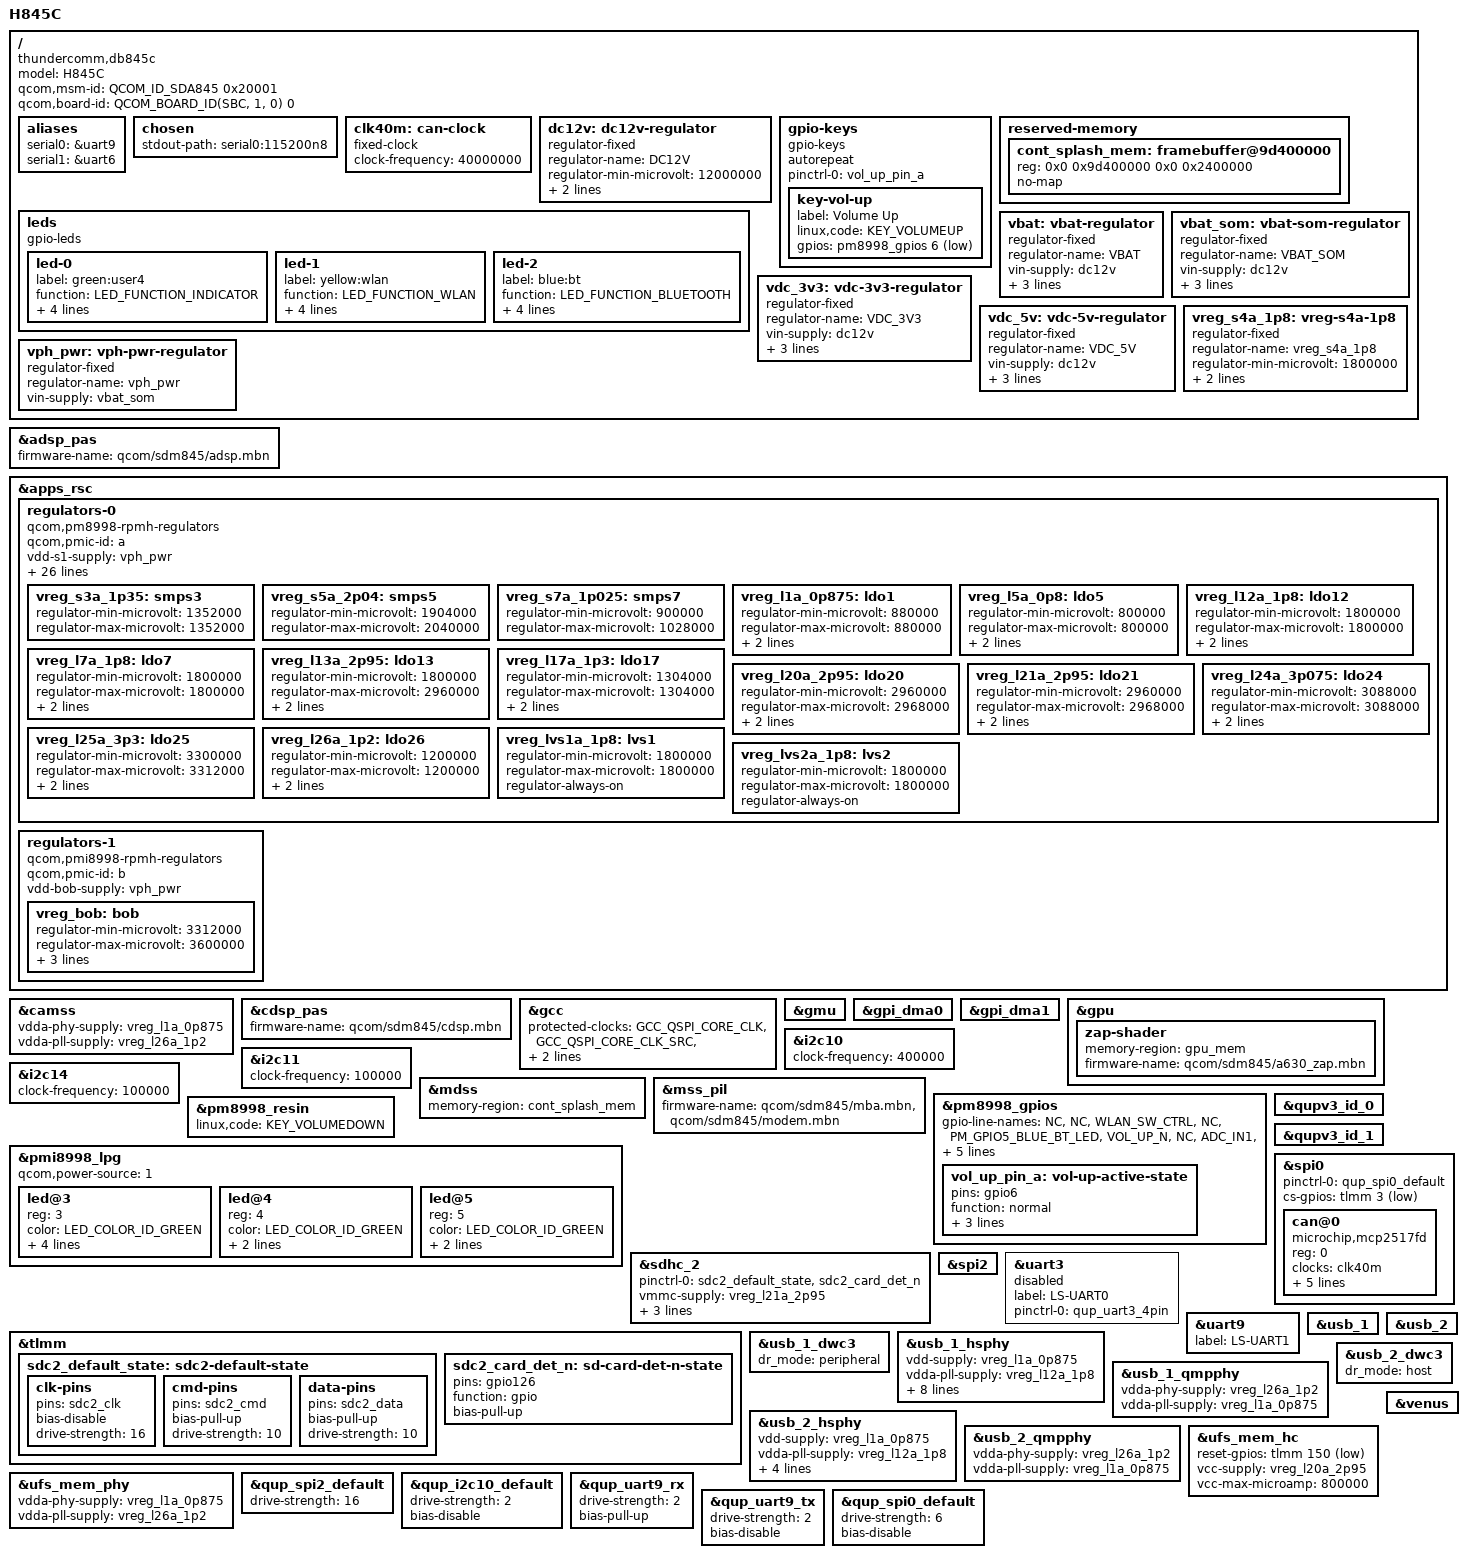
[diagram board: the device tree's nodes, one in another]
// SPDX-License-Identifier: GPL-2.0
/*
 * Copyright (c) 2019, Linaro Ltd.
 */

/dts-v1/;

#include <dt-bindings/arm/qcom,ids.h>
#include <dt-bindings/leds/common.h>
#include <dt-bindings/pinctrl/qcom,pmic-gpio.h>
#include <dt-bindings/regulator/qcom,rpmh-regulator.h>
#include <dt-bindings/sound/qcom,q6afe.h>
#include <dt-bindings/sound/qcom,q6asm.h>
#include "sdm845.dtsi"
#include "pm8998.dtsi"
#include "pmi8998.dtsi"

/ {
	model = "H845C";
	compatible = "thundercomm,db845c", "qcom,sdm845";
	qcom,msm-id = <QCOM_ID_SDA845 0x20001>;
	qcom,board-id = <QCOM_BOARD_ID(SBC, 1, 0) 0>;

	aliases {
		serial0 = &uart9;
		serial1 = &uart6;
	};

	chosen {
		stdout-path = "serial0:115200n8";
	};

	/* Fixed crystal oscillator dedicated to MCP2517FD */
	clk40m: can-clock {
		compatible = "fixed-clock";
		#clock-cells = <0>;
		clock-frequency = <40000000>;
	};

	dc12v: dc12v-regulator {
		compatible = "regulator-fixed";
		regulator-name = "DC12V";
		regulator-min-microvolt = <12000000>;
		regulator-max-microvolt = <12000000>;
		regulator-always-on;
	};

	gpio-keys {
		compatible = "gpio-keys";
		autorepeat;

		pinctrl-names = "default";
		pinctrl-0 = <&vol_up_pin_a>;

		key-vol-up {
			label = "Volume Up";
			linux,code = <KEY_VOLUMEUP>;
			gpios = <&pm8998_gpios 6 GPIO_ACTIVE_LOW>;
		};
	};

	leds {
		compatible = "gpio-leds";

		led-0 {
			label = "green:user4";
			function = LED_FUNCTION_INDICATOR;
			color = <LED_COLOR_ID_GREEN>;
			gpios = <&pm8998_gpios 13 GPIO_ACTIVE_HIGH>;
			default-state = "off";
			panic-indicator;
		};

		led-1 {
			label = "yellow:wlan";
			function = LED_FUNCTION_WLAN;
			color = <LED_COLOR_ID_YELLOW>;
			gpios = <&pm8998_gpios 9 GPIO_ACTIVE_HIGH>;
			linux,default-trigger = "phy0tx";
			default-state = "off";
		};

		led-2 {
			label = "blue:bt";
			function = LED_FUNCTION_BLUETOOTH;
			color = <LED_COLOR_ID_BLUE>;
			gpios = <&pm8998_gpios 5 GPIO_ACTIVE_HIGH>;
			linux,default-trigger = "bluetooth-power";
			default-state = "off";
		};
	};

	reserved-memory {
		/* Cont splash region set up by the bootloader */
		cont_splash_mem: framebuffer@9d400000 {
			reg = <0x0 0x9d400000 0x0 0x2400000>;
			no-map;
		};
	};

	vbat: vbat-regulator {
		compatible = "regulator-fixed";
		regulator-name = "VBAT";

		vin-supply = <&dc12v>;
		regulator-min-microvolt = <4200000>;
		regulator-max-microvolt = <4200000>;
		regulator-always-on;
	};

	vbat_som: vbat-som-regulator {
		compatible = "regulator-fixed";
		regulator-name = "VBAT_SOM";

		vin-supply = <&dc12v>;
		regulator-min-microvolt = <4200000>;
		regulator-max-microvolt = <4200000>;
		regulator-always-on;
	};

	vdc_3v3: vdc-3v3-regulator {
		compatible = "regulator-fixed";
		regulator-name = "VDC_3V3";
		vin-supply = <&dc12v>;
		regulator-min-microvolt = <3300000>;
		regulator-max-microvolt = <3300000>;
		regulator-always-on;
	};

	vdc_5v: vdc-5v-regulator {
		compatible = "regulator-fixed";
		regulator-name = "VDC_5V";

		vin-supply = <&dc12v>;
		regulator-min-microvolt = <500000>;
		regulator-max-microvolt = <500000>;
		regulator-always-on;
	};

	vreg_s4a_1p8: vreg-s4a-1p8 {
		compatible = "regulator-fixed";
		regulator-name = "vreg_s4a_1p8";

		regulator-min-microvolt = <1800000>;
		regulator-max-microvolt = <1800000>;
		regulator-always-on;
	};

	vph_pwr: vph-pwr-regulator {
		compatible = "regulator-fixed";
		regulator-name = "vph_pwr";

		vin-supply = <&vbat_som>;
	};
};

&adsp_pas {
	status = "okay";

	firmware-name = "qcom/sdm845/adsp.mbn";
};

&apps_rsc {
	regulators-0 {
		compatible = "qcom,pm8998-rpmh-regulators";
		qcom,pmic-id = "a";
		vdd-s1-supply = <&vph_pwr>;
		vdd-s2-supply = <&vph_pwr>;
		vdd-s3-supply = <&vph_pwr>;
		vdd-s4-supply = <&vph_pwr>;
		vdd-s5-supply = <&vph_pwr>;
		vdd-s6-supply = <&vph_pwr>;
		vdd-s7-supply = <&vph_pwr>;
		vdd-s8-supply = <&vph_pwr>;
		vdd-s9-supply = <&vph_pwr>;
		vdd-s10-supply = <&vph_pwr>;
		vdd-s11-supply = <&vph_pwr>;
		vdd-s12-supply = <&vph_pwr>;
		vdd-s13-supply = <&vph_pwr>;
		vdd-l1-l27-supply = <&vreg_s7a_1p025>;
		vdd-l2-l8-l17-supply = <&vreg_s3a_1p35>;
		vdd-l3-l11-supply = <&vreg_s7a_1p025>;
		vdd-l4-l5-supply = <&vreg_s7a_1p025>;
		vdd-l6-supply = <&vph_pwr>;
		vdd-l7-l12-l14-l15-supply = <&vreg_s5a_2p04>;
		vdd-l9-supply = <&vreg_bob>;
		vdd-l10-l23-l25-supply = <&vreg_bob>;
		vdd-l13-l19-l21-supply = <&vreg_bob>;
		vdd-l16-l28-supply = <&vreg_bob>;
		vdd-l18-l22-supply = <&vreg_bob>;
		vdd-l20-l24-supply = <&vreg_bob>;
		vdd-l26-supply = <&vreg_s3a_1p35>;
		vin-lvs-1-2-supply = <&vreg_s4a_1p8>;

		vreg_s3a_1p35: smps3 {
			regulator-min-microvolt = <1352000>;
			regulator-max-microvolt = <1352000>;
		};

		vreg_s5a_2p04: smps5 {
			regulator-min-microvolt = <1904000>;
			regulator-max-microvolt = <2040000>;
		};

		vreg_s7a_1p025: smps7 {
			regulator-min-microvolt = <900000>;
			regulator-max-microvolt = <1028000>;
		};

		vreg_l1a_0p875: ldo1 {
			regulator-min-microvolt = <880000>;
			regulator-max-microvolt = <880000>;
			regulator-initial-mode = <RPMH_REGULATOR_MODE_HPM>;
		};

		vreg_l5a_0p8: ldo5 {
			regulator-min-microvolt = <800000>;
			regulator-max-microvolt = <800000>;
			regulator-initial-mode = <RPMH_REGULATOR_MODE_HPM>;
		};

		vreg_l12a_1p8: ldo12 {
			regulator-min-microvolt = <1800000>;
			regulator-max-microvolt = <1800000>;
			regulator-initial-mode = <RPMH_REGULATOR_MODE_HPM>;
		};

		vreg_l7a_1p8: ldo7 {
			regulator-min-microvolt = <1800000>;
			regulator-max-microvolt = <1800000>;
			regulator-initial-mode = <RPMH_REGULATOR_MODE_HPM>;
		};

		vreg_l13a_2p95: ldo13 {
			regulator-min-microvolt = <1800000>;
			regulator-max-microvolt = <2960000>;
			regulator-initial-mode = <RPMH_REGULATOR_MODE_HPM>;
		};

		vreg_l17a_1p3: ldo17 {
			regulator-min-microvolt = <1304000>;
			regulator-max-microvolt = <1304000>;
			regulator-initial-mode = <RPMH_REGULATOR_MODE_HPM>;
		};

		vreg_l20a_2p95: ldo20 {
			regulator-min-microvolt = <2960000>;
			regulator-max-microvolt = <2968000>;
			regulator-initial-mode = <RPMH_REGULATOR_MODE_HPM>;
		};

		vreg_l21a_2p95: ldo21 {
			regulator-min-microvolt = <2960000>;
			regulator-max-microvolt = <2968000>;
			regulator-initial-mode = <RPMH_REGULATOR_MODE_HPM>;
		};

		vreg_l24a_3p075: ldo24 {
			regulator-min-microvolt = <3088000>;
			regulator-max-microvolt = <3088000>;
			regulator-initial-mode = <RPMH_REGULATOR_MODE_HPM>;
		};

		vreg_l25a_3p3: ldo25 {
			regulator-min-microvolt = <3300000>;
			regulator-max-microvolt = <3312000>;
			regulator-initial-mode = <RPMH_REGULATOR_MODE_HPM>;
		};

		vreg_l26a_1p2: ldo26 {
			regulator-min-microvolt = <1200000>;
			regulator-max-microvolt = <1200000>;
			regulator-initial-mode = <RPMH_REGULATOR_MODE_HPM>;
		};

		vreg_lvs1a_1p8: lvs1 {
			regulator-min-microvolt = <1800000>;
			regulator-max-microvolt = <1800000>;
			regulator-always-on;
		};

		vreg_lvs2a_1p8: lvs2 {
			regulator-min-microvolt = <1800000>;
			regulator-max-microvolt = <1800000>;
			regulator-always-on;
		};
	};

	regulators-1 {
		compatible = "qcom,pmi8998-rpmh-regulators";
		qcom,pmic-id = "b";

		vdd-bob-supply = <&vph_pwr>;

		vreg_bob: bob {
			regulator-min-microvolt = <3312000>;
			regulator-max-microvolt = <3600000>;
			regulator-initial-mode = <RPMH_REGULATOR_MODE_AUTO>;
			regulator-allow-bypass;
		};
	};
};

&camss {
	status = "okay";

	vdda-phy-supply = <&vreg_l1a_0p875>;
	vdda-pll-supply = <&vreg_l26a_1p2>;
};

&cdsp_pas {
	status = "okay";
	firmware-name = "qcom/sdm845/cdsp.mbn";
};

&gcc {
	protected-clocks = <GCC_QSPI_CORE_CLK>,
			   <GCC_QSPI_CORE_CLK_SRC>,
			   <GCC_QSPI_CNOC_PERIPH_AHB_CLK>,
			   <GCC_LPASS_Q6_AXI_CLK>,
			   <GCC_LPASS_SWAY_CLK>;
};

&gmu {
	status = "okay";
};

&gpi_dma0 {
	status = "okay";
};

&gpi_dma1 {
	status = "okay";
};

&gpu {
	status = "okay";
	zap-shader {
		memory-region = <&gpu_mem>;
		firmware-name = "qcom/sdm845/a630_zap.mbn";
	};
};

&i2c10 {
	status = "okay";
	clock-frequency = <400000>;
};

&i2c11 {
	/* On Low speed expansion */
	clock-frequency = <100000>;
	status = "okay";
};

&i2c14 {
	/* On Low speed expansion */
	clock-frequency = <100000>;
	status = "okay";
};

&mdss {
	memory-region = <&cont_splash_mem>;
	status = "okay";
};

&mss_pil {
	status = "okay";
	firmware-name = "qcom/sdm845/mba.mbn", "qcom/sdm845/modem.mbn";
};

&pm8998_gpios {
	gpio-line-names =
		"NC",
		"NC",
		"WLAN_SW_CTRL",
		"NC",
		"PM_GPIO5_BLUE_BT_LED",
		"VOL_UP_N",
		"NC",
		"ADC_IN1",
		"PM_GPIO9_YEL_WIFI_LED",
		"NC",
		"NC",
		"NC",
		"PM_GPIO13_GREEN_U4_LED",
		"DIV_CLK2",
		"NC",
		"NC",
		"NC",
		"SMB_STAT",
		"NC",
		"NC",
		"ADC_IN2",
		"OPTION1",
		"WCSS_PWR_REQ",
		"PM845_GPIO24",
		"OPTION2",
		"PM845_SLB";

	vol_up_pin_a: vol-up-active-state {
		pins = "gpio6";
		function = "normal";
		input-enable;
		bias-pull-up;
		qcom,drive-strength = <PMIC_GPIO_STRENGTH_NO>;
	};
};

&pm8998_resin {
	linux,code = <KEY_VOLUMEDOWN>;
	status = "okay";
};

&pmi8998_lpg {
	status = "okay";

	qcom,power-source = <1>;

	led@3 {
		reg = <3>;
		color = <LED_COLOR_ID_GREEN>;
		function = LED_FUNCTION_HEARTBEAT;
		function-enumerator = <3>;

		linux,default-trigger = "heartbeat";
		default-state = "on";
	};

	led@4 {
		reg = <4>;
		color = <LED_COLOR_ID_GREEN>;
		function = LED_FUNCTION_INDICATOR;
		function-enumerator = <2>;
	};

	led@5 {
		reg = <5>;
		color = <LED_COLOR_ID_GREEN>;
		function = LED_FUNCTION_INDICATOR;
		function-enumerator = <1>;
	};
};

&qupv3_id_0 {
	status = "okay";
};

&qupv3_id_1 {
	status = "okay";
};

&sdhc_2 {
	status = "okay";

	pinctrl-names = "default";
	pinctrl-0 = <&sdc2_default_state &sdc2_card_det_n>;

	vmmc-supply = <&vreg_l21a_2p95>;
	vqmmc-supply = <&vreg_l13a_2p95>;

	bus-width = <4>;
	cd-gpios = <&tlmm 126 GPIO_ACTIVE_LOW>;
};

&spi0 {
	status = "okay";
	pinctrl-names = "default";
	pinctrl-0 = <&qup_spi0_default>;
	cs-gpios = <&tlmm 3 GPIO_ACTIVE_LOW>;

	can@0 {
		compatible = "microchip,mcp2517fd";
		reg = <0>;
		clocks = <&clk40m>;
		interrupts-extended = <&tlmm 104 IRQ_TYPE_LEVEL_LOW>;
		spi-max-frequency = <10000000>;
		vdd-supply = <&vdc_5v>;
		xceiver-supply = <&vdc_5v>;
	};
};

&spi2 {
	/* On Low speed expansion */
	status = "okay";
};

&tlmm {
	sdc2_default_state: sdc2-default-state {
		clk-pins {
			pins = "sdc2_clk";
			bias-disable;

			/*
			 * It seems that mmc_test reports errors if drive
			 * strength is not 16 on clk, cmd, and data pins.
			 */
			drive-strength = <16>;
		};

		cmd-pins {
			pins = "sdc2_cmd";
			bias-pull-up;
			drive-strength = <10>;
		};

		data-pins {
			pins = "sdc2_data";
			bias-pull-up;
			drive-strength = <10>;
		};
	};

	sdc2_card_det_n: sd-card-det-n-state {
		pins = "gpio126";
		function = "gpio";
		bias-pull-up;
	};
};

&uart3 {
	label = "LS-UART0";
	pinctrl-0 = <&qup_uart3_4pin>;

	status = "disabled";
};

&uart9 {
	label = "LS-UART1";
	status = "okay";
};

&usb_1 {
	status = "okay";
};

&usb_1_dwc3 {
	dr_mode = "peripheral";
};

&usb_1_hsphy {
	status = "okay";

	vdd-supply = <&vreg_l1a_0p875>;
	vdda-pll-supply = <&vreg_l12a_1p8>;
	vdda-phy-dpdm-supply = <&vreg_l24a_3p075>;

	qcom,imp-res-offset-value = <8>;
	qcom,hstx-trim-value = <QUSB2_V2_HSTX_TRIM_21_6_MA>;
	qcom,preemphasis-level = <QUSB2_V2_PREEMPHASIS_5_PERCENT>;
	qcom,preemphasis-width = <QUSB2_V2_PREEMPHASIS_WIDTH_HALF_BIT>;
};

&usb_1_qmpphy {
	status = "okay";

	vdda-phy-supply = <&vreg_l26a_1p2>;
	vdda-pll-supply = <&vreg_l1a_0p875>;
};

&usb_2 {
	status = "okay";
};

&usb_2_dwc3 {
	dr_mode = "host";
};

&usb_2_hsphy {
	status = "okay";

	vdd-supply = <&vreg_l1a_0p875>;
	vdda-pll-supply = <&vreg_l12a_1p8>;
	vdda-phy-dpdm-supply = <&vreg_l24a_3p075>;

	qcom,imp-res-offset-value = <8>;
	qcom,hstx-trim-value = <QUSB2_V2_HSTX_TRIM_22_8_MA>;
};

&usb_2_qmpphy {
	status = "okay";

	vdda-phy-supply = <&vreg_l26a_1p2>;
	vdda-pll-supply = <&vreg_l1a_0p875>;
};

&ufs_mem_hc {
	status = "okay";

	reset-gpios = <&tlmm 150 GPIO_ACTIVE_LOW>;

	vcc-supply = <&vreg_l20a_2p95>;
	vcc-max-microamp = <800000>;
};

&ufs_mem_phy {
	status = "okay";

	vdda-phy-supply = <&vreg_l1a_0p875>;
	vdda-pll-supply = <&vreg_l26a_1p2>;
};

&venus {
	status = "okay";
};

/* PINCTRL - additions to nodes defined in sdm845.dtsi */
&qup_spi2_default {
	drive-strength = <16>;
};

&qup_i2c10_default {
	drive-strength = <2>;
	bias-disable;
};

&qup_uart9_rx {
	drive-strength = <2>;
	bias-pull-up;
};

&qup_uart9_tx {
	drive-strength = <2>;
	bias-disable;
};

/* PINCTRL - additions to nodes defined in sdm845.dtsi */
&qup_spi0_default {
	drive-strength = <6>;
	bias-disable;
};
